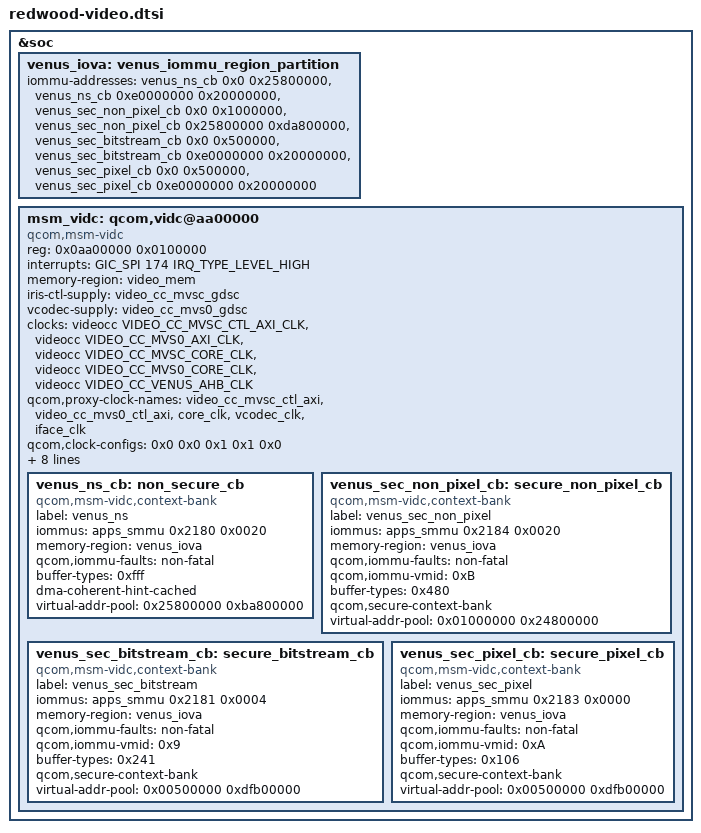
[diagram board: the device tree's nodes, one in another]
// SPDX-License-Identifier: BSD-3-Clause
/*
 * Video for the lahaina msm_vidc (modules/video), from the 5.4 yupik device
 * tree; 6.12 has no video node for Yupik. The firmware loads into video_mem
 * through PAS instead of a PIL node.
 *
 * 6.12 dropped qcom,iommu-dma-addr-pool, and a context bank without an IOVA
 * window gets no IOMMU domain, so reserve everything around the window the
 * 5.4 pool gave each bank (the driver still reads virtual-addr-pool).
 */

#include <dt-bindings/clock/qcom,videocc-sc7280.h>
#include <dt-bindings/interconnect/qcom,yupik.h>
#include <dt-bindings/interrupt-controller/arm-gic.h>

&soc {
	venus_iova: venus_iommu_region_partition {
		iommu-addresses = <&venus_ns_cb 0x0 0x25800000>,
				  <&venus_ns_cb 0xe0000000 0x20000000>,
				  <&venus_sec_non_pixel_cb 0x0 0x1000000>,
				  <&venus_sec_non_pixel_cb 0x25800000 0xda800000>,
				  <&venus_sec_bitstream_cb 0x0 0x500000>,
				  <&venus_sec_bitstream_cb 0xe0000000 0x20000000>,
				  <&venus_sec_pixel_cb 0x0 0x500000>,
				  <&venus_sec_pixel_cb 0xe0000000 0x20000000>;
	};

	msm_vidc: qcom,vidc@aa00000 {
		compatible = "qcom,msm-vidc", "qcom,yupik-vidc";
		status = "okay";
		reg = <0x0aa00000 0x0100000>;
		interrupts = <GIC_SPI 174 IRQ_TYPE_LEVEL_HIGH>;
		memory-region = <&video_mem>;

		/* IOMMU Config */
		#address-cells = <1>;
		#size-cells = <1>;

		/* Supply */
		iris-ctl-supply = <&video_cc_mvsc_gdsc>;
		vcodec-supply = <&video_cc_mvs0_gdsc>;

		/* Clocks */
		clock-names = "video_cc_mvsc_ctl_axi",
			"video_cc_mvs0_ctl_axi", "core_clk",
			"vcodec_clk", "iface_clk";
		clocks = <&videocc VIDEO_CC_MVSC_CTL_AXI_CLK>,
			<&videocc VIDEO_CC_MVS0_AXI_CLK>,
			<&videocc VIDEO_CC_MVSC_CORE_CLK>,
			<&videocc VIDEO_CC_MVS0_CORE_CLK>,
			<&videocc VIDEO_CC_VENUS_AHB_CLK>;
		qcom,proxy-clock-names = "video_cc_mvsc_ctl_axi",
			"video_cc_mvs0_ctl_axi", "core_clk",
			"vcodec_clk", "iface_clk";
		/* Mask: Bit0: Clock Scaling, Bit1: Mem Retention*/
		qcom,clock-configs = <0x0 0x0 0x1 0x1 0x0>;
		qcom,allowed-clock-rates = <133330000 240000000
			335000000 424000000 460000000>;

		qcom,reg-presets = <0xB0088 0x0 0x11>;

		/* Video Firmware ELF image name */
		vidc,firmware-name = "vpu20_1v";

		/* Bus Interconnects */
		interconnect-names = "venus-cnoc", "venus-ddr";
		interconnects = <&gem_noc MASTER_APPSS_PROC
					&cnoc2 SLAVE_VENUS_CFG>,
				<&mmss_noc MASTER_VIDEO_P0
					&mc_virt SLAVE_EBI1>;
		/* Bus BW range (low, high) for each bus */
		qcom,bus-range-kbps = <1000 1000
					1000 8000000>;

		venus_ns_cb: non_secure_cb {
			compatible = "qcom,msm-vidc,context-bank";
			label = "venus_ns";
			iommus = <&apps_smmu 0x2180 0x0020>;
			memory-region = <&venus_iova>;
			qcom,iommu-faults = "non-fatal";
			buffer-types = <0xfff>;
			dma-coherent-hint-cached;
			virtual-addr-pool = <0x25800000 0xba800000>;
		};

		venus_sec_non_pixel_cb: secure_non_pixel_cb {
			compatible = "qcom,msm-vidc,context-bank";
			label = "venus_sec_non_pixel";
			iommus = <&apps_smmu 0x2184 0x0020>;
			memory-region = <&venus_iova>;
			qcom,iommu-faults = "non-fatal";
			qcom,iommu-vmid = <0xB>; /* VMID_CP_NON_PIXEL */
			buffer-types = <0x480>;
			qcom,secure-context-bank;
			virtual-addr-pool = <0x01000000 0x24800000>;
		};

		venus_sec_bitstream_cb: secure_bitstream_cb {
			compatible = "qcom,msm-vidc,context-bank";
			label = "venus_sec_bitstream";
			iommus = <&apps_smmu 0x2181 0x0004>;
			memory-region = <&venus_iova>;
			qcom,iommu-faults = "non-fatal";
			qcom,iommu-vmid = <0x9>; /* VMID_CP_BITSTREAM */
			buffer-types = <0x241>;
			qcom,secure-context-bank;
			virtual-addr-pool = <0x00500000 0xdfb00000>;
		};

		venus_sec_pixel_cb: secure_pixel_cb {
			compatible = "qcom,msm-vidc,context-bank";
			label = "venus_sec_pixel";
			iommus = <&apps_smmu 0x2183 0x0000>;
			memory-region = <&venus_iova>;
			qcom,iommu-faults = "non-fatal";
			qcom,iommu-vmid = <0xA>; /* VMID_CP_PIXEL */
			buffer-types = <0x106>;
			qcom,secure-context-bank;
			virtual-addr-pool = <0x00500000 0xdfb00000>;
		};
	};
};
